# M55M1 register map
File version: 1.0
Registers are 32-bit, read-write, reset 0x0 unless marked. A register's access mark holds for its fields unless they carry their own. Offsets are from the block's base; [hi:lo] are bit positions; lines under a group give offsets from that group; {n}, {i} and the like mark numbered series; 'fields as' and 'values as' point back to an identical list.

## EPWM0 (part 1 of 2) — EPWM Register Map
Base 0x40242000
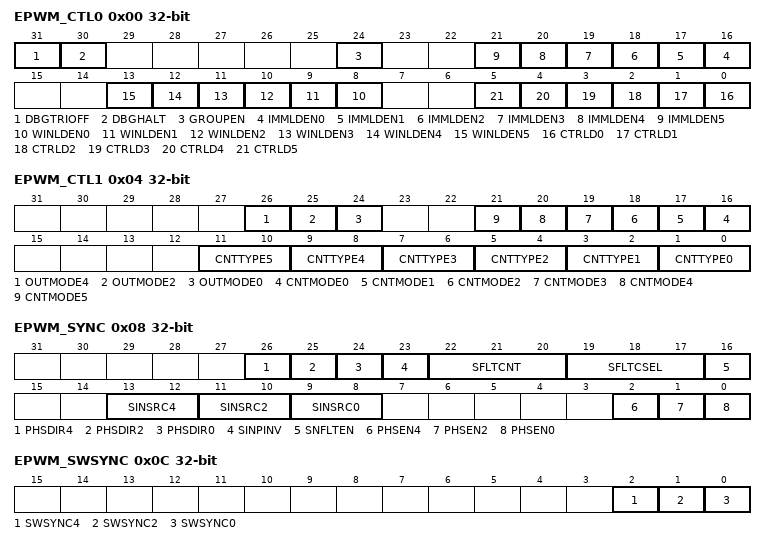
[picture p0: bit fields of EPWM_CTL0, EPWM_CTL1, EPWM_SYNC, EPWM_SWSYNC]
0x00 EPWM_CTL0 — EPWM Control Register 0
  [31] DBGTRIOFF — ICE Debug Mode Acknowledge Disable Bit (Write Protect). EPWM pin will keep output no matter ICE debug mode acknowledged or not. Note: This bit is write protected. Refer toSYS_REGLCTL register.
    0=ICE debug mode acknowledgement effects EPWM output; 1=ICE debug mode acknowledgement disabled
  [30] DBGHALT — ICE Debug Mode Counter Halt (Write Protect). If counter halt is enabled, EPWM all counters will keep current value until exit ICE debug mode. Note: This bit is write protected. Refer toSYS_REGLCTL register.
    0=ICE debug mode counter halt Disabled; 1=ICE debug mode counter halt Enabled
  [24] GROUPEN — Group Function Enable Bit
    0=The output waveform of each EPWM channel are independent; 1=Unify the EPWM_CH2 and EPWM_CH4 to output the same waveform as EPWM_CH0 and unify the EPWM_CH3 and EPWM_CH5 to output the same waveform as EPWM_CH1
  [n+16] IMMLDEN{n} (n=0..5) — Immediately Load Enable Bits. Note: If IMMLDENn is enabled, WINLDENn and CTRLDn will be invalid.
    0=PERIOD will load to PBUF at the end point of each period. CMP will load to CMPBUF at the end point or center point of each period by setting CTRLD bit; 1=PERIOD/CMP will load to PBUF and CMPBUF immediately when software update PERIOD/CMP
  [n+8] WINLDEN{n} (n=0..5) — Window Load Enable Bits
    0=PERIOD will load to PBUF at the end point of each period. CMP will load to CMPBUF at the end point or center point of each period by setting CTRLD bit; 1=PERIOD will load to PBUF at the end point of each period. CMP will load to CMPBUF at the end point of each period when valid reload window is set. The valid reload window is set by software write 1 to EPWM_LOAD register and cleared by hardware after load success
  [n] CTRLD{n} (n=0..5) — Center Re-load. In up-down counter type, PERIOD will load to PBUF at the end point of each period. CMP will load to CMPBUF at the center point of a period.
0x04 EPWM_CTL1 — EPWM Control Register 1
  [26] OUTMODE4 — EPWM Output Mode. Each bit n controls the output mode of corresponding EPWM channel n. Note: When operating in group function, these bits must all set to the same mode.
    0=EPWM independent mode; 1=EPWM complementary mode
  [25] OUTMODE2 — EPWM Output Mode. Each bit n controls the output mode of corresponding EPWM channel n. Note: When operating in group function, these bits must all set to the same mode.
    0=EPWM independent mode; 1=EPWM complementary mode
  [24] OUTMODE0 — EPWM Output Mode. Each bit n controls the output mode of corresponding EPWM channel n. Note: When operating in group function, these bits must all set to the same mode.
    0=EPWM independent mode; 1=EPWM complementary mode
  [n+16] CNTMODE{n} (n=0..5) — EPWM Counter Mode
    0=Auto-reload mode; 1=One-shot mode
  [2n+1:2n] CNTTYPE{n} (n=0..5) — EPWM Counter Behavior Type
    0=Up counter type (supported in capture mode); 1=Down count type (supported in capture mode); 2=Up-down counter type
0x08 EPWM_SYNC — EPWM Synchronization Register
  [26] PHSDIR4 — EPWM Phase Direction Control
    0=Control EPWM counter count decrement after synchronizing; 1=Control EPWM counter count increment after synchronizing
  [25] PHSDIR2 — EPWM Phase Direction Control
    values as PHSDIR4
  [24] PHSDIR0 — EPWM Phase Direction Control
    values as PHSDIR4
  [23] SINPINV — SYNC Input Pin Inverse
    0=The state of pin SYNC is passed to the negative edge detector; 1=The inversed state of pin SYNC is passed to the negative edge detector
  [22:20] SFLTCNT — SYNC Edge Detector Filter Count. The register bits control the counter number of edge detector.
  [19:17] SFLTCSEL — SYNC Edge Detector Filter Clock Selection
    0=Filter clock = HCLK; 1=Filter clock = HCLK/2; 2=Filter clock = HCLK/4; 3=Filter clock = HCLK/8; 4=Filter clock = HCLK/16; 5=Filter clock = HCLK/32; 6=Filter clock = HCLK/64; 7=Filter clock = HCLK/128
  [16] SNFLTEN — EPWM0_SYNC_IN Noise Filter Enable Bits
    0=Noise filter of input pin EPWM0_SYNC_IN Disabled; 1=Noise filter of input pin EPWM0_SYNC_IN Enabled
  [13:12] SINSRC4 — EPWM0_SYNC_IN Source Selection
    0=Synchronize source from SYNC_IN or SWSYNC; 1=Counter equal to 0; 2=Counter equal to EPWM_CMPDATm, m denotes 1, 3, 5; 3=SYNC_OUT will not be generated
  [11:10] SINSRC2 — EPWM0_SYNC_IN Source Selection
    values as SINSRC4
  [9:8] SINSRC0 — EPWM0_SYNC_IN Source Selection
    values as SINSRC4
  [2] PHSEN4 — SYNC Phase Enable Bits
    0=EPWM counter disable to load PHS value; 1=EPWM counter enable to load PHS value
  [1] PHSEN2 — SYNC Phase Enable Bits
    values as PHSEN4
  [0] PHSEN0 — SYNC Phase Enable Bits
    values as PHSEN4
0x0C EPWM_SWSYNC wo — EPWM Software Control Synchronization Register
  [2] SWSYNC4 — Software SYNC Function (Write Only). When SINSRCn (EPWM_SYNC[13:8]) is selected to 0, SYNC_OUT source comes from SYNC_IN or this bit.
  [1] SWSYNC2 — Software SYNC Function (Write Only). When SINSRCn (EPWM_SYNC[13:8]) is selected to 0, SYNC_OUT source comes from SYNC_IN or this bit.
  [0] SWSYNC0 — Software SYNC Function (Write Only). When SINSRCn (EPWM_SYNC[13:8]) is selected to 0, SYNC_OUT source comes from SYNC_IN or this bit.
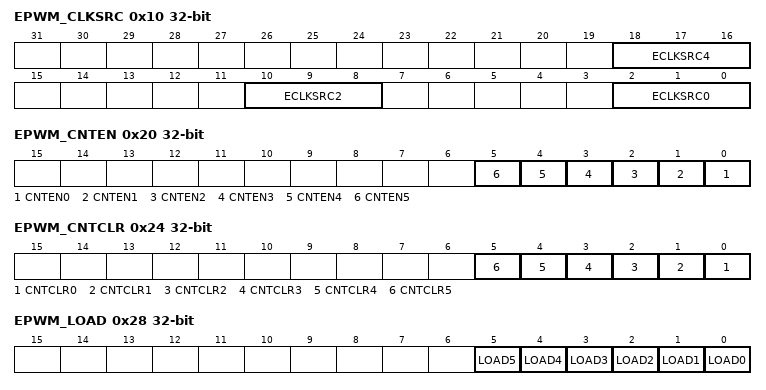
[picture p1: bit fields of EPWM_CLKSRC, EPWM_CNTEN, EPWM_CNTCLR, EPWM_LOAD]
0x10 EPWM_CLKSRC — EPWM Clock Source Register
  [all] fields
    0=EPWMx_CLK, x denotes 0 or 1; {v}=TIMER{v-1} overflow (v=1..4)
  [18:16] ECLKSRC4 — EPWM_CH45 External Clock Source Select
  [10:8] ECLKSRC2 — EPWM_CH23 External Clock Source Select
  [2:0] ECLKSRC0 — EPWM_CH01 External Clock Source Select
0x20 EPWM_CNTEN — EPWM Counter Enable Register
  [all] fields
    0=EPWM Counter and clock prescaler stop running; 1=EPWM Counter and clock prescaler start running
  [n] CNTEN{n} (n=0..5) — EPWM Counter Enable Bits
0x24 EPWM_CNTCLR — EPWM Clear Counter Register
  [all] fields
    0=No effect; 1=Clear 16-bit EPWM counter to 0000H
  [n] CNTCLR{n} (n=0..5) — Clear EPWM Counter Control Bit. It is automatically cleared by hardware. Each bit n controls the corresponding EPWM channel n.
0x28 EPWM_LOAD
  [all] fields
    0=No effect. No load window is set; 1=Set load window of window loading mode. Load window is set
  [n] LOAD{n} (n=0..5) — Re-load EPWM Comparator Register Control Bit
{0x30+4i} EPWM_PERIOD{i} (i=0..5) — EPWM Period Register {i}
  [15:0] PERIOD — EPWM Period Register. Up-Count mode: In this mode, EPWM counter counts from 0 to PERIOD, and restarts from 0.
{0x50+4i} EPWM_CMPDAT{i} (i=0..5) — EPWM Comparator Register {i}
  [15:0] CMP — EPWM Comparator Register. CMP is used to compare with CNT (EPWM_CNTn[15:0]) bits to generate EPWM waveform, interrupt and trigger EADC/LPADC/DAC. In complementary mode, EPWM_CMPDAT0, EPWM_CMPDAT 2, EPWM_CMPDAT4 denote as first compared point, and EPWM_CMPDAT1, EPWM_CMPDAT3, EPWM_CMPDAT5 denote as second compared point for the corresponding 3 complementary pairs EPWM_CH0 and EPWM_CH1, EPWM_CH2 and EPWM_CH3, EPWM_CH4 and EPWM_CH5.
0x80 EPWM_PHS0_1 — EPWM Counter Phase Register 0/1
  [15:0] PHS — EPWM Synchronous Start Phase Bits. PHS determines the EPWM synchronous start phase value. These bits only use in synchronous function.
0x84 EPWM_PHS2_3 — EPWM Counter Phase Register 2/3
  fields as EPWM_PHS0_1
0x88 EPWM_PHS4_5 — EPWM Counter Phase Register 4/5
  fields as EPWM_PHS0_1
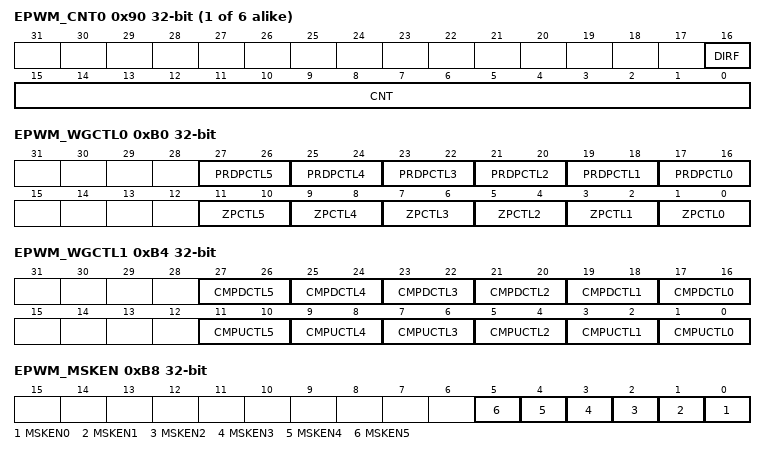
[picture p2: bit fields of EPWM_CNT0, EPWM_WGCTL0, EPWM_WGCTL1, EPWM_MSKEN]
{0x90+4i} EPWM_CNT{i} ro (i=0..5) — EPWM Counter Register {i}
  [16] DIRF — EPWM Direction Indicator Flag (Read Only)
    0=Counter is counting down; 1=Counter is counting up
  [15:0] CNT — EPWM Data Register (Read Only). User can monitor CNT to know the current value in 16-bit period counter.
0xB0 EPWM_WGCTL0 — EPWM Generation Register 0
  [2n+17:2n+16] PRDPCTL{n} (n=0..5) — EPWM Period or Center Point Control. EPWM can control output level when EPWM counter counts to (PERIODn+1). Note: This bit is center point control when EPWM counter operating in up-down counter type.
    0=Do nothing; 1=EPWM period (center) point output Low; 2=EPWM period (center) point output High; 3=EPWM period (center) point output Toggle
  [2n+1:2n] ZPCTL{n} (n=0..5) — EPWM Zero Point Control. EPWM can control output level when EPWM counter counts to 0.
    0=Do nothing; 1=EPWM zero point output Low; 2=EPWM zero point output High; 3=EPWM zero point output Toggle
0xB4 EPWM_WGCTL1 — EPWM Generation Register 1
  [2n+17:2n+16] CMPDCTL{n} (n=0..5) — EPWM Compare Down Point Control. EPWM can control output level when EPWM counter counts down to CMP. Note: In complementary mode, CMPDCTL1, 3, 5 is used as another CMPDCTL for channel 0, 2, 4.
    0=Do nothing; 1=EPWM compare down point output Low; 2=EPWM compare down point output High; 3=EPWM compare down point output Toggle
  [2n+1:2n] CMPUCTL{n} (n=0..5) — EPWM Compare Up Point Control. EPWM can control output level when EPWM counter counts up to CMP. Note: In complementary mode, CMPUCTL1, 3, 5 is used as another CMPUCTL for channel 0, 2, 4.
    0=Do nothing; 1=EPWM compare up point output Low; 2=EPWM compare up point output High; 3=EPWM compare up point output Toggle
0xB8 EPWM_MSKEN — EPWM Mask Enable Register
  [all] fields
    0=EPWM output signal is non-masked; 1=EPWM output signal is masked and output MSKDATn data
  [n] MSKEN{n} (n=0..5) — EPWM Mask Enable Bits. The EPWM output signal will be masked when this bit is enabled. The corresponding EPWM channel n will output MSKDATn (EPWM_MSK[5:0]) data.
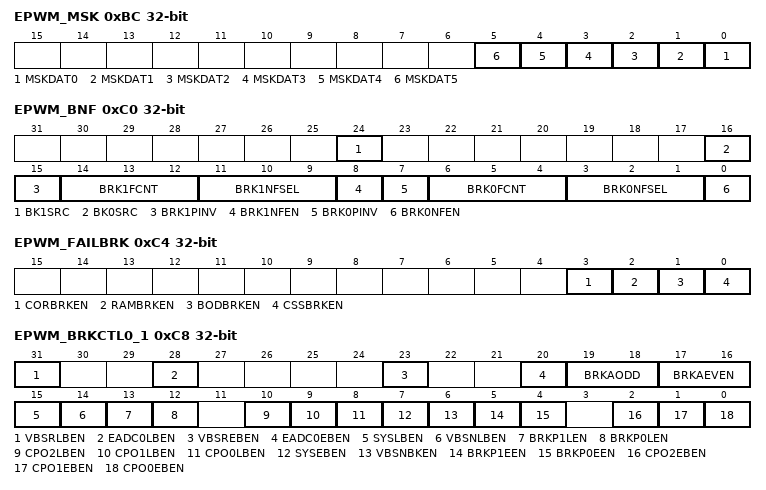
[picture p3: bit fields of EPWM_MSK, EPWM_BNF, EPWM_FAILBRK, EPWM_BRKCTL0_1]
0xBC EPWM_MSK — EPWM Mask Data Register
  [all] fields
    0=Output logic low to EPWM channel n; 1=Output logic high to EPWM channel n
  [n] MSKDAT{n} (n=0..5) — EPWM Mask Data Bit. This data bit control the state of EPWMn output pin, if corresponding mask function is enabled.
0xC0 EPWM_BNF — EPWM Brake Noise Filter Register
  [24] BK1SRC — Brake 1 Pin Source Select. For EPWM0 setting:
    0=Brake 1 pin source come from EPWM0_BRAKE1. Brake 1 pin source come from EPWM1_BRAKE1; 1=Brake 1 pin source come from EPWM1_BRAKE1. Brake 1 pin source come from EPWM0_BRAKE1
  [16] BK0SRC — Brake 0 Pin Source Select. For EPWM0 setting:
    0=Brake 0 pin source come from EPWM0_BRAKE0. Brake 0 pin source come from EPWM1_BRAKE0; 1=Brake 0 pin source come from EPWM1_BRAKE0. Brake 0 pin source come from EPWM0_BRAKE0
  [15] BRK1PINV — Brake 1 Pin Inverse
    0=brake pin event will be detected if EPWMx_BRAKE1 pin status transfer from low to high in edge-detect, or pin status is high in level-detect; 1=brake pin event will be detected if EPWMx_BRAKE1 pin status transfer from high to low in edge-detect, or pin status is low in level-detect
  [14:12] BRK1FCNT — Brake 1 Edge Detector Filter Count. The register bits control the Brake1 filter counter to count from 0 to BRK1FCNT.
  [11:9] BRK1NFSEL — Brake 1 Edge Detector Filter Clock Selection
    values as EPWM_SYNC.SFLTCSEL
  [8] BRK1NFEN — EPWM Brake 1 Noise Filter Enable Bit
    0=Noise filter of EPWM Brake 1 Disabled; 1=Noise filter of EPWM Brake 1 Enabled
  [7] BRK0PINV — Brake 0 Pin Inverse
    0=brake pin event will be detected if EPWMx_BRAKE0 pin status transfer from low to high in edge-detect, or pin status is high in level-detect; 1=brake pin event will be detected if EPWMx_BRAKE0 pin status transfer from high to low in edge-detect, or pin status is low in level-detect
  [6:4] BRK0FCNT — Brake 0 Edge Detector Filter Count. The register bits control the Brake0 filter counter to count from 0 to BRK0FCNT.
  [3:1] BRK0NFSEL — Brake 0 Edge Detector Filter Clock Selection
    values as EPWM_SYNC.SFLTCSEL
  [0] BRK0NFEN — EPWM Brake 0 Noise Filter Enable Bit
    0=Noise filter of EPWM Brake 0 Disabled; 1=Noise filter of EPWM Brake 0 Enabled
0xC4 EPWM_FAILBRK — EPWM System Fail Brake Control Register
  [3] CORBRKEN — Core Lockup Detection Trigger EPWM Brake Function 0 Enable Bit
    0=Brake Function triggered by Core lockup detection Disabled; 1=Brake Function triggered by Core lockup detection Enabled
  [2] RAMBRKEN — SRAM Parity Error Detection Trigger EPWM Brake Function 0 Enable Bit
    0=Brake Function triggered by SRAM parity error detection Disabled; 1=Brake Function triggered by SRAM parity error detection Enabled
  [1] BODBRKEN — Brown-out Detection Trigger EPWM Brake Function 0 Enable Bit
    0=Brake Function triggered by BOD Disabled; 1=Brake Function triggered by BOD Enabled
  [0] CSSBRKEN — Clock Security System Detection Trigger EPWM Brake Function 0 Enable Bit
    0=Brake Function triggered by CSS detection Disabled; 1=Brake Function triggered by CSS detection Enabled
0xC8 EPWM_BRKCTL0_1 — EPWM Brake Edge Detect Control Register 0/1
  [31] VBSRLBEN — UTCPD0 VBUS Source Disable As Level-detect Brake Source (Write Protect). Note: This bit is write protected. Refer toSYS_REGLCTL register.
    0=UTCPD0 VBUS source disable as level-detect brake source Disabled; 1=UTCPD0 VBUS source disable as level-detect brake source Enabled
  [28] EADC0LBEN — Enable EADC0 Result Monitor as Level-detect Brake Source (Write Protect). Note: This bit is write protected. Refer to SYS_REGLCTL register.
    0=EADC0RM as level-detect brake source Disabled; 1=EADC0RM as level-detect brake source Enabled
  [23] VBSREBEN — UTCPD0 VBUS Source Disable As Edge-detect Brake Source (Write Protect). Note: This bit is write protected. Refer toSYS_REGLCTL register.
    0=UTCPD0 VBUS source disable as edge-detect brake source Disabled; 1=UTCPD0 VBUS source disable as edge-detect brake source Enabled
  [20] EADC0EBEN — Enable EADC0 Result Monitor as Edge-detect Brake Source (Write Protect). Note: This bit is write protected. Refer to SYS_REGLCTL register.
    0=EADC0RM as edge-detect brake source Disabled; 1=EADC0RM as edge-detect brake source Enabled
  [19:18] BRKAODD — EPWM Brake Action Select for Odd Channel (Write Protect). Note: This bit is write protected. Refer to SYS_REGLCTL register.
    0=EPWMx brake event will not affect odd channels output; 1=EPWM odd channel output tri-state when EPWMx brake event happened; 2=EPWM odd channel output low level when EPWMx brake event happened; 3=EPWM odd channel output high level when EPWMx brake event happened
  [17:16] BRKAEVEN — EPWM Brake Action Select for Even Channel (Write Protect). Note: This bit is write protected. Refer toSYS_REGLCTL register.
    0=EPWMx brake event will not affect even channels output; 1=EPWM even channel output tri-state when EPWMx brake event happened; 2=EPWM even channel output low level when EPWMx brake event happened; 3=EPWM even channel output high level when EPWMx brake event happened
  [15] SYSLBEN — Enable System Fail As Level-detect Brake Source (Write Protect). Note: This bit is write protected. Refer toSYS_REGLCTL register.
    0=System Fail condition as level-detect brake source Disabled; 1=System Fail condition as level-detect brake source Enabled
  [14] VBSNLBEN — UTCPD0 VBUS Sink Disable As Level-detect Brake Source (Write Protect). Note: This bit is write protected. Refer toSYS_REGLCTL register.
    0=UTCPD0 VBUS sink disable as level-detect brake source Disabled; 1=UTCPD0 VBUS sink disable as level-detect brake source Enabled
  [13] BRKP1LEN — Enable BKP1 Pin As Level-detect Brake Source (Write Protect). Note: This bit is write protected. Refer toSYS_REGLCTL register.
    0=EPWMx_BRAKE1 pin as level-detect brake source Disabled; 1=EPWMx_BRAKE1 pin as level-detect brake source Enabled
  [12] BRKP0LEN — Enable BKP0 Pin As Level-detect Brake Source (Write Protect). Note: This bit is write protected. Refer toSYS_REGLCTL register.
    0=EPWMx_BRAKE0 pin as level-detect brake source Disabled; 1=EPWMx_BRAKE0 pin as level-detect brake source Enabled
  [10] CPO2LBEN — Enable ACMP2_O Digital Output As Level-detect Brake Source (Write Protect). Note: This bit is write protected. Refer toSYS_REGLCTL register.
    0=ACMP2_O as level-detect brake source Disabled; 1=ACMP2_O as level-detect brake source Enabled
  [9] CPO1LBEN — Enable ACMP1_O Digital Output As Level-detect Brake Source (Write Protect). Note: This bit is write protected. Refer toSYS_REGLCTL register.
    0=ACMP1_O as level-detect brake source Disabled; 1=ACMP1_O as level-detect brake source Enabled
  [8] CPO0LBEN — Enable ACMP0_O Digital Output As Level-detect Brake Source (Write Protect). Note: This bit is write protected. Refer toSYS_REGLCTL register.
    0=ACMP0_O as level-detect brake source Disabled; 1=ACMP0_O as level-detect brake source Enabled
  [7] SYSEBEN — Enable System Fail As Edge-detect Brake Source (Write Protect). Note: This bit is write protected. Refer toSYS_REGLCTL register.
    0=System Fail condition as edge-detect brake source Disabled; 1=System Fail condition as edge-detect brake source Enabled
  [6] VBSNBKEN — UTCPD0 VBUS Sink Disable As Edge-detect Brake Source (Write Protect). Note: This bit is write protected. Refer toSYS_REGLCTL register.
    0=UTCPD0 VBUS sink disable as edge-detect brake source Disabled; 1=UTCPD0 VBUS sink disable as edge-detect brake source Enabled
  [5] BRKP1EEN — Enable EPWMx_BRAKE1 Pin As Edge-detect Brake Source (Write Protect). Note: This bit is write protected. Refer toSYS_REGLCTL register.
    0=EPWMx_BRAKE1 pin as edge-detect brake source Disabled; 1=EPWMx_BRAKE1 pin as edge-detect brake source Enabled
  [4] BRKP0EEN — Enable EPWMx_BRAKE0 Pin As Edge-detect Brake Source (Write Protect). Note: This bit is write protected. Refer toSYS_REGLCTL register.
    0=EPWMx_BRAKE0 pin as edge-detect brake source Disabled; 1=EPWMx_BRAKE0 pin as edge-detect brake source Enabled
  [2] CPO2EBEN — Enable ACMP2_O Digital Output As Edge-detect Brake Source (Write Protect). Note: This bit is write protected. Refer toSYS_REGLCTL register.
    0=ACMP2_O as edge-detect brake source Disabled; 1=ACMP2_O as edge-detect brake source Enabled
  [1] CPO1EBEN — Enable ACMP1_O Digital Output As Edge-detect Brake Source (Write Protect). Note: This bit is write protected. Refer toSYS_REGLCTL register.
    0=ACMP1_O as edge-detect brake source Disabled; 1=ACMP1_O as edge-detect brake source Enabled
  [0] CPO0EBEN — Enable ACMP0_O Digital Output As Edge-detect Brake Source (Write Protect). Note: This bit is write protected. Refer toSYS_REGLCTL register.
    0=ACMP0_O as edge-detect brake source Disabled; 1=ACMP0_O as edge-detect brake source Enabled
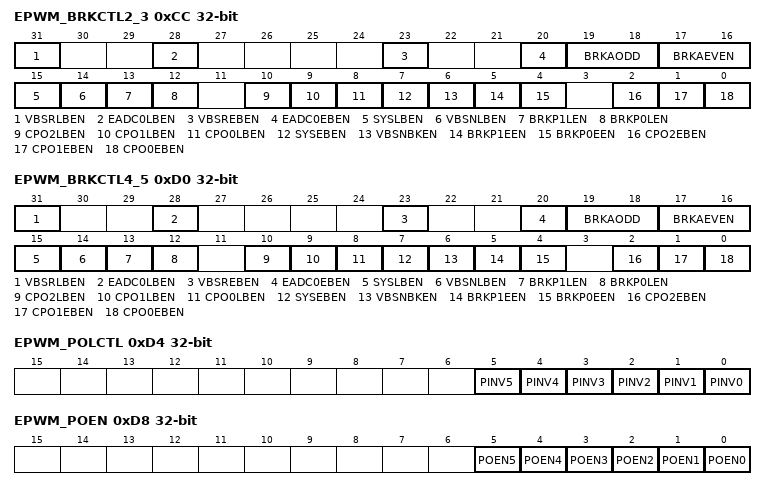
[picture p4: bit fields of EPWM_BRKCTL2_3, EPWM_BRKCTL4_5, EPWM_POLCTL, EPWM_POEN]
0xCC EPWM_BRKCTL2_3 — EPWM Brake Edge Detect Control Register 2/3
  fields as EPWM_BRKCTL0_1
0xD0 EPWM_BRKCTL4_5 — EPWM Brake Edge Detect Control Register 4/5
  fields as EPWM_BRKCTL0_1
0xD4 EPWM_POLCTL — EPWM Pin Polar Inverse Register
  [all] fields
    0=EPWMx_CHn output pin polar inverse Disabled; 1=EPWMx_CHn output pin polar inverse Enabled
  [n] PINV{n} (n=0..5) — EPWM PIN Polar Inverse Control. The register controls polarity state of EPWMx_CHn output pin.
0xD8 EPWM_POEN — EPWM Output Enable Register
  [all] fields
    0=EPWMx_CHn pin at tri-state; 1=EPWMx_CHn pin in output mode
  [n] POEN{n} (n=0..5) — EPWM Pin Output Enable Bits
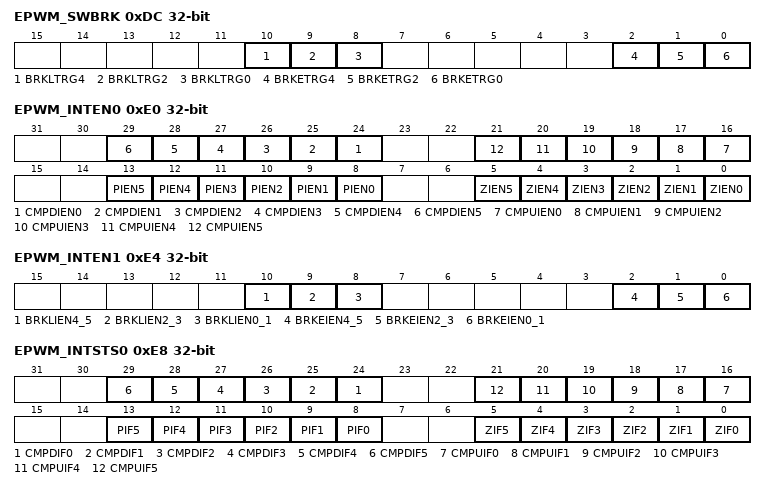
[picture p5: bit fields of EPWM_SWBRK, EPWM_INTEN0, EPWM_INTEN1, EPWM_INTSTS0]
0xDC EPWM_SWBRK wo — EPWM Software Brake Control Register
  [10] BRKLTRG4 — EPWM Level Brake Software Trigger (Write Only) (Write Protect). Write 1 to this bit will trigger level brake, and set BRKLIFn to 1 in EPWM_INTSTS1 register. Note: This bit is write protected. Refer to SYS_REGLCTL register.
  [9] BRKLTRG2 — EPWM Level Brake Software Trigger (Write Only) (Write Protect). Write 1 to this bit will trigger level brake, and set BRKLIFn to 1 in EPWM_INTSTS1 register. Note: This bit is write protected. Refer to SYS_REGLCTL register.
  [8] BRKLTRG0 — EPWM Level Brake Software Trigger (Write Only) (Write Protect). Write 1 to this bit will trigger level brake, and set BRKLIFn to 1 in EPWM_INTSTS1 register. Note: This bit is write protected. Refer to SYS_REGLCTL register.
  [2] BRKETRG4 — EPWM Edge Brake Software Trigger (Write Only) (Write Protect). Write 1 to this bit will trigger edge brake, and set BRKEIFn to 1 in EPWM_INTSTS1 register. Note: This bit is write protected. Refer to SYS_REGLCTL register.
  [1] BRKETRG2 — EPWM Edge Brake Software Trigger (Write Only) (Write Protect). Write 1 to this bit will trigger edge brake, and set BRKEIFn to 1 in EPWM_INTSTS1 register. Note: This bit is write protected. Refer to SYS_REGLCTL register.
  [0] BRKETRG0 — EPWM Edge Brake Software Trigger (Write Only) (Write Protect). Write 1 to this bit will trigger edge brake, and set BRKEIFn to 1 in EPWM_INTSTS1 register. Note: This bit is write protected. Refer to SYS_REGLCTL register.
0xE0 EPWM_INTEN0 — EPWM Interrupt Enable Register 0
  [n+24] CMPDIEN{n} (n=0..5) — EPWM Compare Down Count Interrupt Enable Bits. Note: In complementary mode, CMPDIEN1, 3, 5 is used as another CMPDIEN for channel 0, 2, 4.
    0=Compare down count interrupt Disabled; 1=Compare down count interrupt Enabled
  [n+16] CMPUIEN{n} (n=0..5) — EPWM Compare Up Count Interrupt Enable Bits. Note: In complementary mode, CMPUIEN1, 3, 5 is used as another CMPUIEN for channel 0, 2, 4.
    0=Compare up count interrupt Disabled; 1=Compare up count interrupt Enabled
  [n+8] PIEN{n} (n=0..5) — EPWM Period Point Interrupt Enable Bits. Note 1: When up-down counter type period point means center point. Note 2: Odd channels will read always 0 at complementary mode.
    0=Period point interrupt Disabled; 1=Period point interrupt Enabled
  [n] ZIEN{n} (n=0..5) — EPWM Zero Point Interrupt Enable Bits. Note: Odd channels will read always 0 at complementary mode.
    0=Zero point interrupt Disabled; 1=Zero point interrupt Enabled
0xE4 EPWM_INTEN1 — EPWM Interrupt Enable Register 1
  [10] BRKLIEN4_5 — EPWM Level-detect Brake Interrupt Enable for Channel4/5 (Write Protect). Note: This bit is write protected. Refer toSYS_REGLCTL register.
    0=Level-detect Brake interrupt for channel4/5 Disabled; 1=Level-detect Brake interrupt for channel4/5 Enabled
  [9] BRKLIEN2_3 — EPWM Level-detect Brake Interrupt Enable for Channel2/3 (Write Protect). Note: This bit is write protected. Refer toSYS_REGLCTL register.
    0=Level-detect Brake interrupt for channel2/3 Disabled; 1=Level-detect Brake interrupt for channel2/3 Enabled
  [8] BRKLIEN0_1 — EPWM Level-detect Brake Interrupt Enable for Channel0/1 (Write Protect). Note: This bit is write protected. Refer toSYS_REGLCTL register.
    0=Level-detect Brake interrupt for channel0/1 Disabled; 1=Level-detect Brake interrupt for channel0/1 Enabled
  [2] BRKEIEN4_5 — EPWM Edge-detect Brake Interrupt Enable for Channel4/5 (Write Protect). Note: This bit is write protected. Refer toSYS_REGLCTL register.
    0=Edge-detect Brake interrupt for channel4/5 Disabled; 1=Edge-detect Brake interrupt for channel4/5 Enabled
  [1] BRKEIEN2_3 — EPWM Edge-detect Brake Interrupt Enable for Channel2/3 (Write Protect). Note: This bit is write protected. Refer toSYS_REGLCTL register.
    0=Edge-detect Brake interrupt for channel2/3 Disabled; 1=Edge-detect Brake interrupt for channel2/3 Enabled
  [0] BRKEIEN0_1 — EPWM Edge-detect Brake Interrupt Enable for Channel0/1 (Write Protect). Note: This bit is write protected. Refer toSYS_REGLCTL register.
    0=Edge-detect Brake interrupt for channel0/1 Disabled; 1=Edge-detect Brake interrupt for channel0/1 Enabled
0xE8 EPWM_INTSTS0 — EPWM Interrupt Flag Register 0
  [n+24] CMPDIF{n} (n=0..5) — EPWM Compare Down Count Interrupt Flag. Flag is set by hardware when EPWM counter down count and reaches EPWM_CMPDATn, software can clear this bit by writing 1 to it. Note: In complementary mode, CMPDIF1, 3, 5 is used as another CMPDIF for channel 0, 2, 4.
  [n+16] CMPUIF{n} (n=0..5) — EPWM Compare Up Count Interrupt Flag. Flag is set by hardware when EPWM counter up count and reaches EPWM_CMPDATn, software can clear this bit by writing 1 to it. Note: In complementary mode, CMPUIF1, 3, 5 is used as another CMPUIF for channel 0, 2, 4.
  [n+8] PIF{n} (n=0..5) — EPWM Period Point Interrupt Flag. This bit is set by hardware when EPWM counter reaches EPWM_PERIODn. Note: This bit can be cleared to 0 by software writing 1.
  [n] ZIF{n} (n=0..5) — EPWM Zero Point Interrupt Flag. This bit is set by hardware when EPWM counter reaches 0. Note: This bit can be cleared to 0 by software writing 1
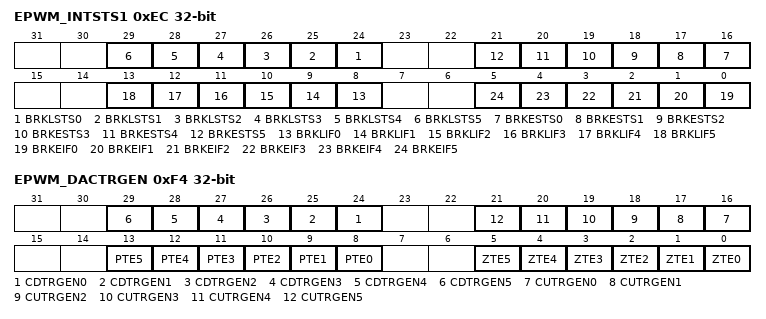
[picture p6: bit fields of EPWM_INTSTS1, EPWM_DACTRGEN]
0xEC EPWM_INTSTS1 — EPWM Interrupt Flag Register 1
  [n+24] BRKLSTS{n} ro (n=0..5) — EPWM Channel N Level-detect Brake Status (Read Only). Note: This bit is read only and auto cleared by hardware. When enabled brake source return to high level, EPWM will release brake state until current EPWM period finished. The EPWM waveform will start output from next full EPWM period.
    0=EPWM channel n level-detect brake state is released; 1=When EPWM channel n level-detect brake detects a falling edge of any enabled brake source; this flag will be set to indicate the EPWM channel n at brake state
  [n+16] BRKESTS{n} ro (n=0..5) — EPWM Channel N Edge-detect Brake Status (Read Only). Note: This bit is read only and auto cleared by hardware. When edge-detect brake interrupt flag is cleared, EPWM will release brake state until current EPWM period finished. The EPWM waveform will start output from next full EPWM period.
    0=EPWM channel n edge-detect brake state is released; 1=When EPWM channel n edge-detect brake detects a falling edge of any enabled brake source; this flag will be set to indicate the EPWM channel n at brake state
  [n+8] BRKLIF{n} (n=0..5) — EPWM Channel N Level-detect Brake Interrupt Flag (Write Protect). Note: This bit is write protected. Refer toSYS_REGLCTL register.
    0=EPWM channel n level-detect brake event do not happened; 1=When EPWM channel n level-detect brake event happened, this bit is set to 1, writing 1 to clear
  [n] BRKEIF{n} (n=0..5) — EPWM Channel N Edge-detect Brake Interrupt Flag (Write Protect). Note: This bit is write protected. Refer toSYS_REGLCTL register.
    0=EPWM channel n edge-detect brake event do not happened; 1=When EPWM channel n edge-detect brake event happened, this bit is set to 1, writing 1 to clear
0xF4 EPWM_DACTRGEN — EPWM Trigger DAC Enable Register
  [n+24] CDTRGEN{n} (n=0..5) — EPWM Compare Down Count Point Trigger DAC Enable Bits. EPWM can trigger DAC to start action when EPWM counter down count to CMP if this bit is set to1. Note 1: This bit should keep at 0 when EPWM counter operating in up counter type. Note 2: In complementary mode, CDTRGEN1, 3, 5 is used as another CDTRGEN for channel 0, 2, 4.
    0=EPWM Compare Down count point trigger DAC function Disabled; 1=EPWM Compare Down count point trigger DAC function Enabled
  [n+16] CUTRGEN{n} (n=0..5) — EPWM Compare Up Count Point Trigger DAC Enable Bits. EPWM can trigger DAC to start action when EPWM counter counts up to CMP if this bit is set to1. Note 1: This bit should keep at 0 when EPWM counter operating in down counter type. Note 2: In complementary mode, CUTRGEN1, 3, 5 is used as another CUTRGEN for channel 0, 2, 4.
    0=EPWM Compare Up point trigger DAC function Disabled; 1=EPWM Compare Up point trigger DAC function Enabled
  [n+8] PTE{n} (n=0..5) — EPWM Period Point Trigger DAC Enable Bits. EPWM can trigger DAC to start action when EPWM counter counts up to (PERIODn+1) if this bit is set to1.
    0=EPWM period point trigger DAC function Disabled; 1=EPWM period point trigger DAC function Enabled
  [n] ZTE{n} (n=0..5) — EPWM Zero Point Trigger DAC Enable Bits. EPWM can trigger EADC/DAC/DMA to start action when EPWM counter down count to zero if this bit is set to1.
    values as PTE0

## EPWM1 (part 1 of 2) — EPWM Register Map
Base 0x40282000
Registers as EPWM0; these are added or differ:
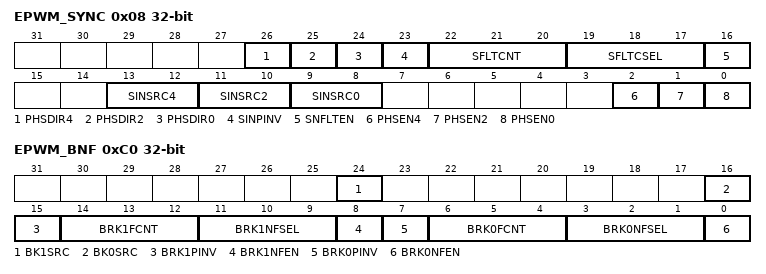
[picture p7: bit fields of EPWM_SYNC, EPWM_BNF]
0x08 EPWM_SYNC — EPWM Synchronization Register
  fields as EPWM0.EPWM_SYNC
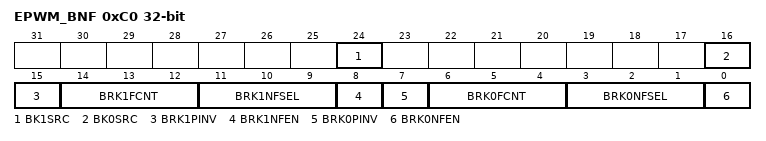
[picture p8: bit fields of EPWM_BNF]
0xC0 EPWM_BNF — EPWM Brake Noise Filter Register
  fields as EPWM0.EPWM_BNF

## EPWM0_NS (part 1 of 2) — EPWM Register Map
Base 0x50242000
Same registers: EPWM1_NS 0x50282000
Registers as EPWM1; these are added or differ:
0xC0 EPWM_BNF — EPWM Brake Noise Filter Register
  fields as EPWM0.EPWM_BNF
